# ESP32-C5 register map
Vendor: ESPRESSIF SYSTEMS (SHANGHAI) CO., LTD.; Series: ESP32 C-Series; File version: 1
CPU: RV32IMAC r0p0, little endian, no MPU, no FPU, 0 interrupt priority bits
Address unit: 32 bits
Registers are 32-bit, read-write, reset 0x0 unless marked. A register's access mark holds for its fields unless they carry their own. Offsets are from the block's base; [hi:lo] are bit positions; lines under a group give offsets from that group; {n}, {i} and the like mark numbered series.

## HP_APM — HP_APM Peripheral
Base 0x60099000
0x00 REGION_FILTER_EN reset 0x1 — Region filter enable register
  [15:0] REGION_FILTER_EN — Configure bit 0 (0-15) to enable region 0.\\ 0: disable \\ 1: enable \\
{0x4+0xC*i} REGION{i}_ADDR_START (i=0..15) — Region address register
  [31:0] REGION_ADDR_START — Configures start address of region %s.
{0x8+0xC*i} REGION{i}_ADDR_END (i=0..15) reset 0xFFFFFFFF — Region address register
  [31:0] REGION_ADDR_END — Configures end address of region %s.
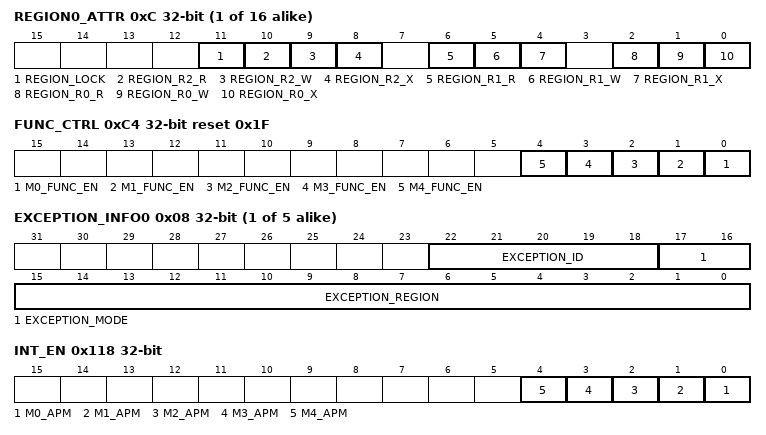
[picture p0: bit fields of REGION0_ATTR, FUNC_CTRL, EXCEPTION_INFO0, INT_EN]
{0xC+0xC*i} REGION{i}_ATTR (i=0..15) — Region access authority attribute register
  [11] REGION_LOCK — Set 1 to lock region0 configuration
  [10] REGION_R2_R — Configures the read authority of REE_MODE 2 in region %s.
  [9] REGION_R2_W — Configures the write authority of REE_MODE 2 in region %s.
  [8] REGION_R2_X — Configures the execution authority of REE_MODE 2 in region %s.
  [6] REGION_R1_R — Configures the read authority of REE_MODE 1 in region %s.
  [5] REGION_R1_W — Configures the write authority of REE_MODE 1 in region %s.
  [4] REGION_R1_X — Configures the execution authority of REE_MODE 1 in region %s.
  [2] REGION_R0_R — Configures the read authority of REE_MODE 0 in region %s.
  [1] REGION_R0_W — Configures the write authority of REE_MODE 0 in region %s.
  [0] REGION_R0_X — Configures the execution authority of REE_MODE 0 in region %s.
0xC4 FUNC_CTRL reset 0x1F — APM function control register
  [n] M{n}_FUNC_EN (n=0..4) — PMS M{n} function enable
{0xC8+0x10*i} M{i} (i=0..4) group — Cluster M{i}, containing M?_STATUS, M?_STATUS_CLR, M?_EXCEPTION_INFO0, M?_EXCEPTION_INFO1
  0x00 STATUS ro — M0 status register
    [1:0] EXCEPTION_STATUS — Represents exception status.\\ bit0: 1 represents authority_exception \\ bit1: 1 represents space_exception \\
  0x04 STATUS_CLR wo — M0 status clear register
    [0] EXCEPTION_STATUS_CLR — Configures to clear exception status.
  0x08 EXCEPTION_INFO0 ro — M0 exception_info0 register
    [22:18] EXCEPTION_ID — Represents exception id information.
    [17:16] EXCEPTION_MODE — Represents exception mode.
    [15:0] EXCEPTION_REGION — Represents exception region.
  0x0C EXCEPTION_INFO1 ro — M0 exception_info1 register
    [31:0] EXCEPTION_ADDR — Represents exception addr.
0x118 INT_EN — APM interrupt enable register
  [n] M{n}_APM (n=0..4) — Configures to enable APM M{n} interrupt.\\ 0: disable \\ 1: enable \\
0x7F8 CLOCK_GATE reset 0x1 — Clock gating register
  [0] CLK_EN — Configures whether to keep the clock always on.\\ 0: enable automatic clock gating \\ 1: keep the clock always on \\
0x7FC DATE — Version control register

## MODEM_SYSCON
Base 0x600A9C00
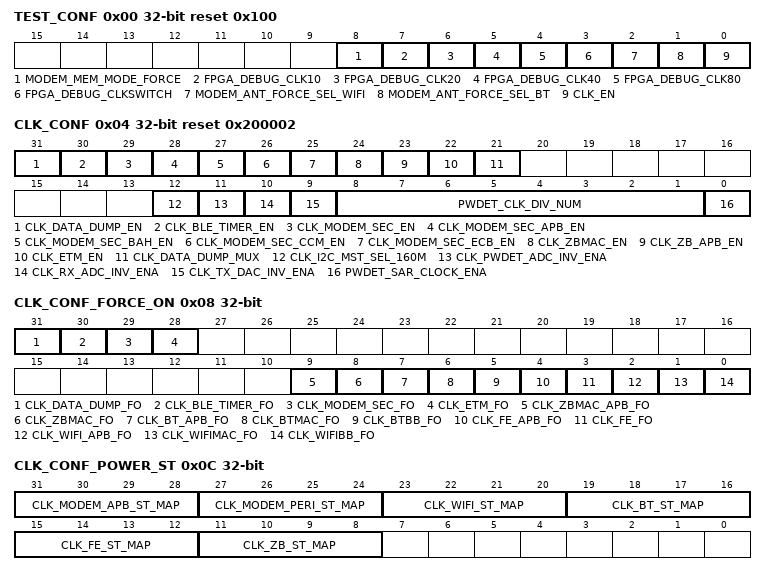
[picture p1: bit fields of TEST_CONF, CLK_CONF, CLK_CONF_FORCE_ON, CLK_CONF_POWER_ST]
0x00 TEST_CONF reset 0x100
  [8] MODEM_MEM_MODE_FORCE, [7] FPGA_DEBUG_CLK10, [6] FPGA_DEBUG_CLK20, [5] FPGA_DEBUG_CLK40, [4] FPGA_DEBUG_CLK80, [3] FPGA_DEBUG_CLKSWITCH, [2] MODEM_ANT_FORCE_SEL_WIFI, [1] MODEM_ANT_FORCE_SEL_BT, [0] CLK_EN
0x04 CLK_CONF reset 0x200002
  [31] CLK_DATA_DUMP_EN, [30] CLK_BLE_TIMER_EN, [29] CLK_MODEM_SEC_EN, [28] CLK_MODEM_SEC_APB_EN, [27] CLK_MODEM_SEC_BAH_EN, [26] CLK_MODEM_SEC_CCM_EN, [25] CLK_MODEM_SEC_ECB_EN, [24] CLK_ZBMAC_EN, [23] CLK_ZB_APB_EN, [22] CLK_ETM_EN, [21] CLK_DATA_DUMP_MUX, [12] CLK_I2C_MST_SEL_160M, [11] CLK_PWDET_ADC_INV_ENA, [10] CLK_RX_ADC_INV_ENA, [9] CLK_TX_DAC_INV_ENA, [8:1] PWDET_CLK_DIV_NUM, [0] PWDET_SAR_CLOCK_ENA
0x08 CLK_CONF_FORCE_ON
  [31] CLK_DATA_DUMP_FO, [30] CLK_BLE_TIMER_FO, [29] CLK_MODEM_SEC_FO, [28] CLK_ETM_FO, [9] CLK_ZBMAC_APB_FO, [8] CLK_ZBMAC_FO, [7] CLK_BT_APB_FO, [6] CLK_BTMAC_FO, [5] CLK_BTBB_FO, [4] CLK_FE_APB_FO, [3] CLK_FE_FO, [2] CLK_WIFI_APB_FO, [1] CLK_WIFIMAC_FO, [0] CLK_WIFIBB_FO
0x0C CLK_CONF_POWER_ST
  [31:28] CLK_MODEM_APB_ST_MAP, [27:24] CLK_MODEM_PERI_ST_MAP, [23:20] CLK_WIFI_ST_MAP, [19:16] CLK_BT_ST_MAP, [15:12] CLK_FE_ST_MAP, [11:8] CLK_ZB_ST_MAP
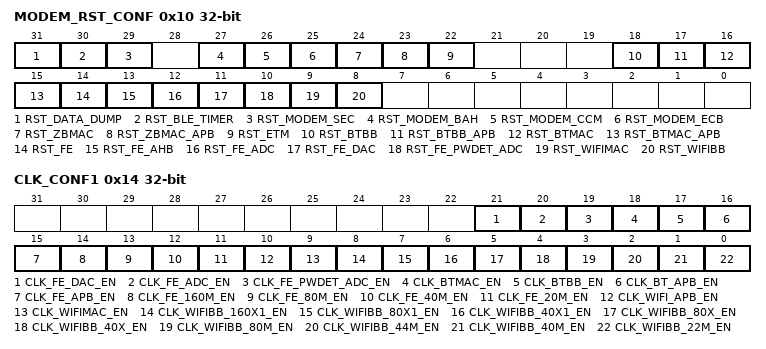
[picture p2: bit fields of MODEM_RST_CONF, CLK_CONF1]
0x10 MODEM_RST_CONF
  [31] RST_DATA_DUMP, [30] RST_BLE_TIMER, [29] RST_MODEM_SEC, [27] RST_MODEM_BAH, [26] RST_MODEM_CCM, [25] RST_MODEM_ECB, [24] RST_ZBMAC, [23] RST_ZBMAC_APB, [22] RST_ETM, [18] RST_BTBB, [17] RST_BTBB_APB, [16] RST_BTMAC, [15] RST_BTMAC_APB, [14] RST_FE, [13] RST_FE_AHB, [12] RST_FE_ADC, [11] RST_FE_DAC, [10] RST_FE_PWDET_ADC, [9] RST_WIFIMAC, [8] RST_WIFIBB
0x14 CLK_CONF1
  [21] CLK_FE_DAC_EN, [20] CLK_FE_ADC_EN, [19] CLK_FE_PWDET_ADC_EN, [18] CLK_BTMAC_EN, [17] CLK_BTBB_EN, [16] CLK_BT_APB_EN, [15] CLK_FE_APB_EN, [14] CLK_FE_160M_EN, [13] CLK_FE_80M_EN, [12] CLK_FE_40M_EN, [11] CLK_FE_20M_EN, [10] CLK_WIFI_APB_EN, [9] CLK_WIFIMAC_EN, [8] CLK_WIFIBB_160X1_EN, [7] CLK_WIFIBB_80X1_EN, [6] CLK_WIFIBB_40X1_EN, [5] CLK_WIFIBB_80X_EN, [4] CLK_WIFIBB_40X_EN, [3] CLK_WIFIBB_80M_EN, [2] CLK_WIFIBB_44M_EN, [1] CLK_WIFIBB_40M_EN, [0] CLK_WIFIBB_22M_EN
0x18 WIFI_BB_CFG
0x1C FE_CFG
0x20 MEM_RF1_CONF reset 0x2070
  [31:0] MODEM_RF1_MEM_AUX_CTRL
0x24 MEM_RF2_CONF
  [31:0] MODEM_RF2_MEM_AUX_CTRL
0x28 DATE
